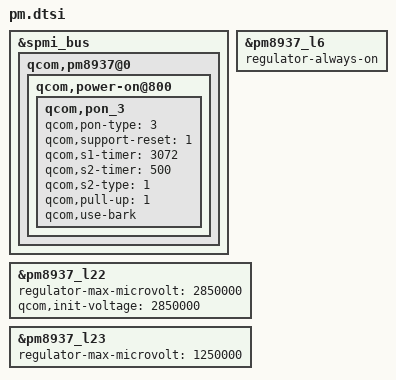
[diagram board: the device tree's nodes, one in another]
&spmi_bus {
	qcom,pm8937@0 {
		qcom,power-on@800 {
	                qcom,pon_3 {
				qcom,pon-type = <3>;
				qcom,support-reset = <1>;
				qcom,s1-timer = <3072>;
				qcom,s2-timer = <500>;
				qcom,s2-type = <1>;
				qcom,pull-up = <1>;
				qcom,use-bark;
			};
		};
	};
};

&pm8937_l6 {
	regulator-always-on;
};

&pm8937_l22 {
	regulator-max-microvolt = <2850000>;
	qcom,init-voltage = <2850000>;
};

&pm8937_l23 {
	regulator-max-microvolt = <1250000>;
};
